# ATA5787 device description
Architecture: AVR8; Family: megaAVR
Registers are 8-bit, access not given, no defined reset value unless marked. A register's access mark holds for its fields unless they carry their own. Offsets are from the block's base; [hi:lo] are bit positions; {n}, {i} and the like mark numbered series; 'fields as' and 'values as' point back to an identical list.

## FRSYNC
Instances: FRSYNC 0x00
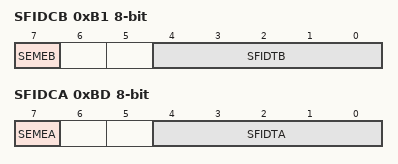
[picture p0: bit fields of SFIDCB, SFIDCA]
0xB1 SFIDCB — Start Frame ID Configuration Path B
  [7] SEMEB — Serial Mode Enable Path B
  [4:0] SFIDTB — Start Frame ID Threshold Path B
0xB2 SFIDLB bits used 5:0 — Start Frame ID Length Path B
0xB3 WUPTB bits used 4:0 — Wake-Up Pattern Threshold Path B
0xB4 WUPLB bits used 5:0 — Wake-Up Pattern Length Path B
{0xB4+i} SFID{i}B (i=1..4) — Start Frame ID Byte {i} Path B
{0xB8+i} WUP{i}B (i=1..4) — Wake-Up Pattern Byte {i} Path B
0xBD SFIDCA — Start Frame ID Configuration Path A
  [7] SEMEA — Serial Mode Enable Path A
  [4:0] SFIDTA — Start Frame ID Threshold Path A
0xBE SFIDLA bits used 5:0 — Start Frame ID Length Path A
0xBF WUPTA bits used 4:0 — Wake-Up Pattern Threshold Path A
0xC0 WUPLA bits used 5:0 — Wake-Up Pattern Length Path A
{0xC0+i} SFID{i}A (i=1..4) — Start Frame ID Byte {i} Path A
{0xC4+i} WUP{i}A (i=1..4) — Wake-Up Pattern Byte {i} Path A

## GPIOREGS
Instances: GPIOREGS 0x00
0x3A GPIOR0 — General Purpose I/O Register 0
{0x38+i} GPIOR{i} (i=3..6) — General Purpose I/O Register {i}
0x44 GPIOR1 — General Purpose I/O Register 1
0x45 GPIOR2 — General Purpose I/O Register 2

## IDCHK
Instances: IDCHK 0x00
{0x156+i} IDB{i} (i=0..3) — ID Check Byte {i}
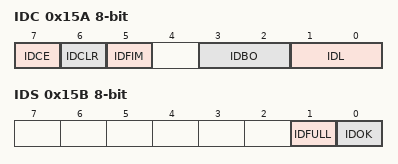
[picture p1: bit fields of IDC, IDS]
0x15A IDC — ID Check Configuration
  [7] IDCE — ID Check Execute
  [6] IDCLR — ID Clear
  [5] IDFIM — ID Full Interrupt Mask
  [3:2] IDBO — ID Byte Offset
  [1:0] IDL — ID Length
0x15B IDS — ID Check Status
  [1] IDFULL — ID Full Flag
  [0] IDOK — ID Check Ok Flag

## INT
Instances: INT 0x00
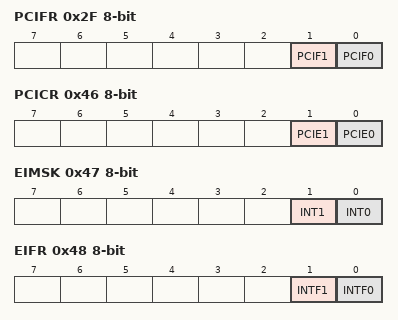
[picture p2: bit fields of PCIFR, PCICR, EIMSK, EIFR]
0x2F PCIFR — Pin Change Interrupt Flag Register
  [1] PCIF1 — Pin Change Interrupt Flag 1
  [0] PCIF0 — Pin Change Interrupt Flag 0
0x46 PCICR — Pin Change Interrupt Control Register
  [1] PCIE1 — Pin Change Interrupt Enable 1
  [0] PCIE0 — Pin Change Interrupt Enable 0
0x47 EIMSK — External Interrupt Mask
  [1] INT1 — External Interrupt Request 1 Enable
  [0] INT0 — External Interrupt Request 0 Enable
0x48 EIFR — External Interrupt Flag Register
  [1] INTF1 — External Interrupt Flag 1
  [0] INTF0 — External Interrupt Flag 0
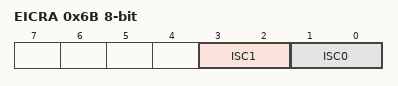
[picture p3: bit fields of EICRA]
0x6B EICRA — External Interrupt Control Register A
  [3:2] ISC1 — Interrupt Sense Control 1
    0=Low Level of INTX; 1=Logical Change of INTX; 2=Falling Edge of INTX; 3=Rising Edge of INTX
  [1:0] ISC0 — Interrupt Sense Control 0
    values as ISC1
0x6C PCMSK0 — Pin Change Mask Register 0
  [7:0] PCINT — Pin Change Enable Mask
0x6D PCMSK1 — Pin Change Mask Register 1
  [5:0] PCINT (bit 8 of the value upward) — Pin Change Enable Mask

## LIN_UART
Instances: LIN_UART 0x00
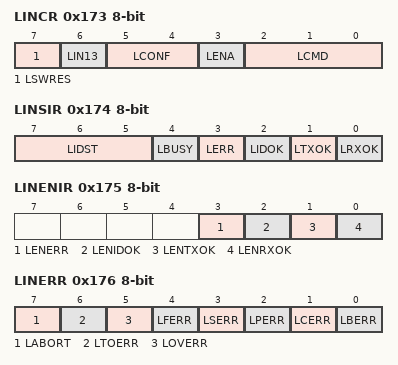
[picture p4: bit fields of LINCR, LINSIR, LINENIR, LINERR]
0x173 LINCR — LIN/UART Control Register
  [7] LSWRES — LIN/UART Software Reset
  [6] LIN13 — LIN 1.3 Mode
  [5:4] LCONF — LIN/UART Configuration
  [3] LENA — LIN/UART Enable
  [2:0] LCMD — LIN/UART Command and Mode
0x174 LINSIR — LIN Status and Interrupt Register
  [7:5] LIDST — LIN Identifier Status
  [4] LBUSY — LIN/UART Busy Flag
  [3] LERR — LIN/UART Error Flag
  [2] LIDOK — LIN Identifier Ok Flag
  [1] LTXOK — LIN/UART Transmit Ok Flag
  [0] LRXOK — LIN/UART Receive Ok Flag
0x175 LINENIR — LIN/UART Enable Interrupt Register
  [3] LENERR — LIN/UART Enable Error Interrupt
  [2] LENIDOK — LIN Enable Identifier Ok Interrupt
  [1] LENTXOK — LIN/UART Enable Transmit Ok Interrupt
  [0] LENRXOK — LIN/UART Enable Receive Ok Interrupt
0x176 LINERR — LIN/UART Error Register
  [7] LABORT — LIN Abort Flag
  [6] LTOERR — LIN Frame Time Out Error Flag
  [5] LOVERR — LIN/UART Overrun Error Flag
  [4] LFERR — LIN/UART Framing Error Flag
  [3] LSERR — LIN Synchronization Error Flag
  [2] LPERR — LIN Parity Error Flag
  [1] LCERR — LIN Checksum Error Flag
  [0] LBERR — LIN Bit Error Flag
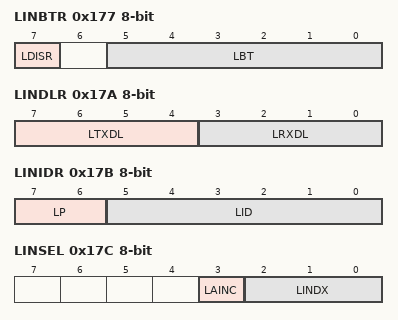
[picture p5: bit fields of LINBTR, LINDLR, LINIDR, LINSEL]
0x177 LINBTR — LIN/UART Bit Timing Register
  [7] LDISR — LIN/UART Disable Bit Timing Resynchronization
  [5:0] LBT — LIN/UART Bit Timing
0x178 LINBRRL — LIN/UART Baud Rate Register Low Byte
  [7:0] LDIV — LIN/UART Clock Divider
0x179 LINBRRH — LIN/UART Baud Rate Register High Byte
  [3:0] LDIV (bit 8 of the value upward) — LIN/UART Clock Divider
0x17A LINDLR — LIN/UART Data Length Register
  [7:4] LTXDL — LIN Transmit Data Length
  [3:0] LRXDL — LIN Receive Data Length
0x17B LINIDR — LIN/UART Identifier Register
  [7:6] LP — LIN Parity
  [5:0] LID — LIN Identifier
0x17C LINSEL — LIN/UART Data Buffer Selection
  [3] LAINC — LIN Auto Increment of Data Buffer Index Disable
  [2:0] LINDX — LIN Data Buffer Index
0x17D LINDAT — LIN/UART Data Register
  [7:0] LDATA — LIN/UART Data
